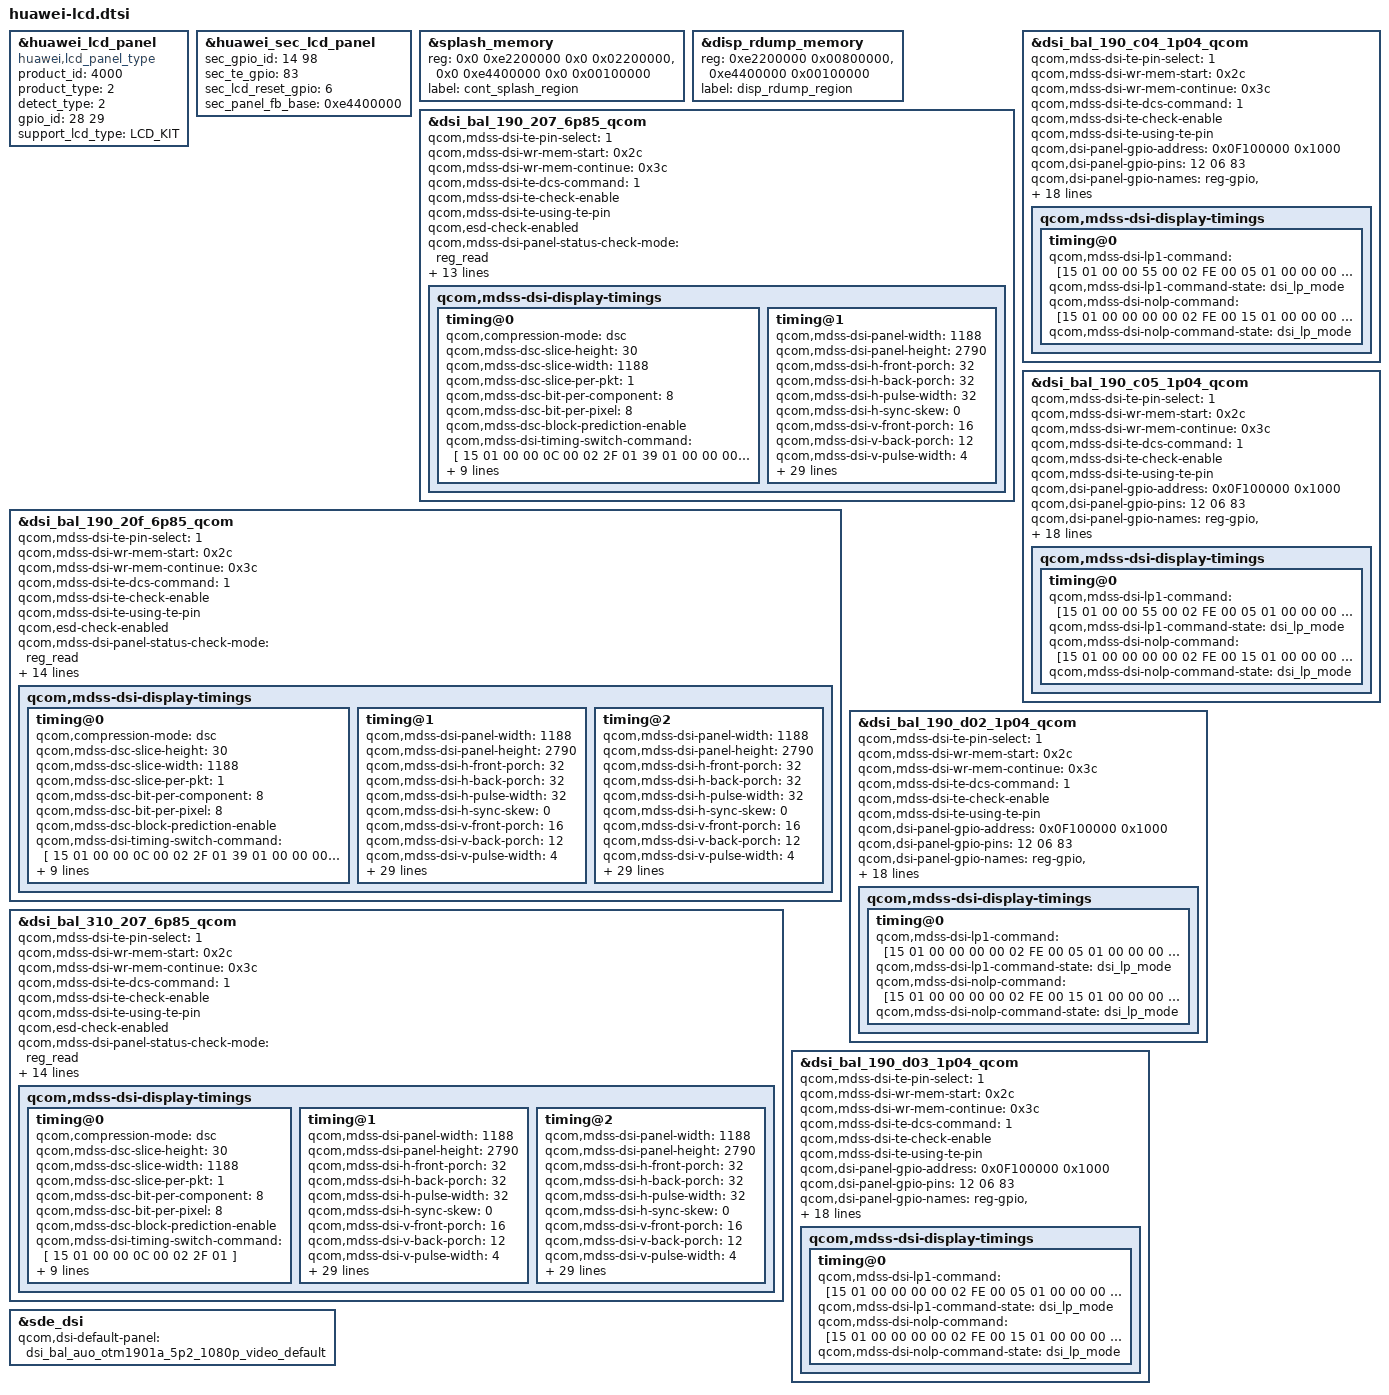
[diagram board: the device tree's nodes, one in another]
#include "../../../lcdkit3.0/bal/devkit_lcd_kit.dtsi"
&huawei_lcd_panel {
	compatible = "huawei,lcd_panel_type";
	/* auto_key_info @ name: product_id type: uint32 default: 0 */
	product_id = <4000>;
	/* auto_key_info @ name: product_type type: uint32 default: 0 */
	product_type = <2>;
	detect_type = <2>;
	/* auto_key_info @ name: gpio_id[2] type: int default: 0 */
	gpio_id = <28 29>;
	support_lcd_type = "LCD_KIT";
};

&huawei_sec_lcd_panel {
	/* auto_key_info @ name: sec_gpio_id[2] type: int default: 0 */
	sec_gpio_id = <14 98>;
	/* auto_key_info @ name: sec_te_gpio type: int default: 0 */
	sec_te_gpio = <83>;
	/* auto_key_info @ name: sec_lcd_reset_gpio type: int default: 0 */
	sec_lcd_reset_gpio = <6>;
	/* auto_key_info @ name: sec_panel_fb_base type: UINTN default: 0 */
	sec_panel_fb_base = <0xe4400000>;
};

&splash_memory {
	reg = <0x0 0xe2200000 0x0 0x02200000>, <0x0 0xe4400000 0x0 0x00100000>;
	label = "cont_splash_region";
};

&disp_rdump_memory {
	reg = <0xe2200000 0x00800000>, <0xe4400000 0x00100000>;
	label = "disp_rdump_region";
};

&dsi_bal_190_207_6p85_qcom {
	qcom,mdss-dsi-te-pin-select = <1>;
	qcom,mdss-dsi-wr-mem-start = <0x2c>;
	qcom,mdss-dsi-wr-mem-continue = <0x3c>;
	qcom,mdss-dsi-te-dcs-command = <1>;
	qcom,mdss-dsi-te-check-enable;
	qcom,mdss-dsi-te-using-te-pin;
	qcom,esd-check-enabled;
	qcom,mdss-dsi-panel-status-check-mode = "reg_read";
	qcom,mdss-dsi-panel-status-command = [06 01 00 01 00 00 01 0a];
	qcom,mdss-dsi-panel-status-command-state = "dsi_lp_mode";
	qcom,mdss-dsi-panel-status-value = <0x9c>;
	qcom,mdss-dsi-panel-status-read-length = <1>;
	qcom,dsi-panel-gpio-address = <0x0F100000 0x1000>;
	qcom,dsi-panel-gpio-pins = <12 24 82>;
	qcom,dsi-panel-gpio-names = "reg-gpio", "reset-gpio", "platform-te-gpio";
	qcom,dynamic-mode-switch-enabled;
	qcom,dynamic-mode-switch-type = "dynamic-resolution-switch-immediate";
	qcom,mdss-dsi-display-timings {
		timing@0 {
			qcom,compression-mode = "dsc";
			qcom,mdss-dsc-slice-height = <30>;
			qcom,mdss-dsc-slice-width = <1188>;
			qcom,mdss-dsc-slice-per-pkt = <1>;
			qcom,mdss-dsc-bit-per-component = <8>;
			qcom,mdss-dsc-bit-per-pixel = <8>;
			qcom,mdss-dsc-block-prediction-enable;
			qcom,mdss-dsi-timing-switch-command = [
				15 01 00 00 0C 00 02 2F 01
				39 01 00 00 00 00 06 F0 55 AA 52 08 00
				39 01 00 00 00 00 0F C5 55 55 55 55 00 05 00 55 55 55 55 55 55 55
			];
			qcom,mdss-dsi-lp1-command = [39 01 00 00 00 00 06 F0 55 AA 52 08 00
				15 01 00 00 00 00 02 6F 0D
				15 01 00 00 00 00 02 B5 51
				15 01 00 00 00 00 02 2F 01
				39 01 00 00 00 00 0F C5 55 55 55 55 00 05 00 55 55 55 55 55 55 55
				05 01 00 00 22 00 01 39
 				15 01 00 00 00 00 02 65 01
				05 01 00 00 00 00 01 2C];
			qcom,mdss-dsi-lp1-command-state = "dsi_lp_mode";
			qcom,mdss-dsi-nolp-command = [39 01 00 00 00 00 06 F0 55 AA 52 08 00
				15 01 00 00 00 00 02 6F 0D
				15 01 00 00 00 00 02 B5 50
				15 01 00 00 22 00 02 65 00
				39 01 00 00 00 00 05 51 00 00 00 00
				05 01 00 00 00 00 01 38
				05 01 00 00 00 00 01 2C
				15 01 00 00 22 00 02 2F 01
				39 01 00 00 00 00 0F C5 55 55 55 55 00 05 00 55 55 55 55 55 55 55];
			qcom,mdss-dsi-nolp-command-state = "dsi_lp_mode";
			qcom,panel-roi-alignment = <0 0 594 30 1188 30>;
			qcom,partial-update-enabled = "single_roi";
			qcom,mdss-mdp-transfer-time-us = <15245>;
		};
		timing@1 {
			qcom,mdss-dsi-panel-width = <1188>;
			qcom,mdss-dsi-panel-height = <2790>;
			qcom,mdss-dsi-h-front-porch = <32>;
			qcom,mdss-dsi-h-back-porch = <32>;
			qcom,mdss-dsi-h-pulse-width = <32>;
			qcom,mdss-dsi-h-sync-skew = <0>;
			qcom,mdss-dsi-v-front-porch = <16>;
			qcom,mdss-dsi-v-back-porch = <12>;
			qcom,mdss-dsi-v-pulse-width = <4>;
			qcom,mdss-dsi-panel-framerate = <90>;
			qcom,mdss-dsi-panel-phy-timings= [00 1B 06 06 16 20 07
				07 07 07 02 04 17 0B];
			qcom,display-topology  = <1 1 1>;
			qcom,default-topology-index  = <0>;
			qcom,mdss-dsi-on-command = [39 01 00 00 00 00 06 F0 55 AA 52 00 00
				39 01 00 00 00 00 05 FF AA 55 A5 80
				39 01 00 00 00 00 05 FF AA 55 A5 81
				39 01 00 00 00 00 05 FF AA 55 A5 00
				05 01 00 00 00 00 01 35
				15 01 00 00 00 00 02 53 20
				39 01 00 00 00 00 05 2A 00 00 04 A3
				39 01 00 00 00 00 05 2B 00 00 0A E5
				15 01 00 00 00 00 02 82 A8
				15 01 00 00 00 00 02 03 01
				15 01 00 00 00 00 02 90 01
				39 01 00 00 00 00 13 91 89 28 00 1E C2 00 03 52 03 FC 00 10 03 50 01 8B 10 F0
				05 01 00 00 00 00 01 2C
				15 01 00 00 00 00 02 2F 02
				39 01 00 00 00 00 06 F0 55 AA 52 08 00
				39 01 00 00 00 00 0F C5 55 55 55 55 00 05 00 55 55 55 55 55 55 55
				39 01 00 00 00 00 06 F0 55 AA 52 08 00
				15 01 00 00 00 00 02 6F 05
				39 01 00 00 00 00 06 B5 7F 4E 1C 4F 54
				15 01 00 00 00 00 02 6F 0B
				39 01 00 00 00 00 05 B5 4E 25 50 54
				15 01 00 00 00 00 02 6F 10
				39 01 00 00 00 00 06 B5 1C 1C 1C 1C 1C
				39 01 00 00 00 00 06 F0 55 AA 52 08 00
				15 01 00 00 00 00 02 6F 08
				15 01 00 00 00 00 02 B5 50
				15 01 00 00 00 00 02 6F 0D
				15 01 00 00 00 00 02 B5 50
				39 01 00 00 00 00 06 F0 55 AA 52 08 07
				15 01 00 00 00 00 02 C0 00
				05 01 00 00 50 00 01 11
				05 01 00 00 00 00 01 29];
			qcom,mdss-dsi-on-command-state = "dsi_lp_mode";
			qcom,mdss-dsi-off-command = [39 01 00 00 00 00 06 F0 55 AA 52 08 00
				15 01 00 00 00 00 02 6F 0D
				15 01 00 00 00 00 02 B5 50
				15 01 00 00 22 00 02 65 00
				05 01 00 00 00 00 01 38
				05 01 00 00 00 00 01 2C
				05 01 00 00 00 00 01 28
				05 01 00 00 50 00 01 10];
			qcom,mdss-dsi-off-command-state = "dsi_lp_mode";
			qcom,mdss-dsi-lp1-command = [39 01 00 00 00 00 06 F0 55 AA 52 08 00
				15 01 00 00 00 00 02 6F 0D
				15 01 00 00 00 00 02 B5 51
				15 01 00 00 00 00 02 2F 01
				39 01 00 00 00 00 0F C5 55 55 55 55 00 05 00 55 55 55 55 55 55 55
				05 01 00 00 22 00 01 39
 				15 01 00 00 00 00 02 65 01
				05 01 00 00 00 00 01 2C];
			qcom,mdss-dsi-lp1-command-state = "dsi_lp_mode";
			qcom,mdss-dsi-nolp-command = [39 01 00 00 00 00 06 F0 55 AA 52 08 00
				15 01 00 00 00 00 02 6F 0D
				15 01 00 00 00 00 02 B5 50
				15 01 00 00 22 00 02 65 00
				39 01 00 00 00 00 05 51 00 00 00 00
				05 01 00 00 00 00 01 38
				05 01 00 00 00 00 01 2C
				15 01 00 00 22 00 02 2F 02
				39 01 00 00 00 00 0F C5 55 55 55 55 00 05 00 55 55 55 55 55 55 55];
			qcom,mdss-dsi-nolp-command-state = "dsi_lp_mode";
			qcom,compression-mode = "dsc";
			qcom,mdss-dsc-slice-height = <30>;
			qcom,mdss-dsc-slice-width = <1188>;
			qcom,mdss-dsc-slice-per-pkt = <1>;
			qcom,mdss-dsc-bit-per-component = <8>;
			qcom,mdss-dsc-bit-per-pixel = <8>;
			qcom,mdss-dsc-block-prediction-enable;
			qcom,mdss-dsi-timing-switch-command = [
				15 01 00 00 09 00 02 2F 02
				39 01 00 00 00 00 06 F0 55 AA 52 08 00
				39 01 00 00 00 00 0F C5 55 55 55 55 00 05 00 55 55 55 55 55 55 55
			];
			qcom,panel-roi-alignment = <0 0 594 30 1188 30>;
			qcom,partial-update-enabled = "single_roi";
			qcom,mdss-mdp-transfer-time-us = <10164>;
		};
	};
};


&dsi_bal_190_20f_6p85_qcom {
	qcom,mdss-dsi-te-pin-select = <1>;
	qcom,mdss-dsi-wr-mem-start = <0x2c>;
	qcom,mdss-dsi-wr-mem-continue = <0x3c>;
	qcom,mdss-dsi-te-dcs-command = <1>;
	qcom,mdss-dsi-te-check-enable;
	qcom,mdss-dsi-te-using-te-pin;
	qcom,esd-check-enabled;
	qcom,mdss-dsi-panel-status-check-mode = "reg_read";
	qcom,mdss-dsi-panel-status-command = [06 01 00 01 00 00 01 0a];
	qcom,mdss-dsi-panel-status-command-state = "dsi_lp_mode";
	qcom,mdss-dsi-panel-status-value = <0x9c>;
	qcom,mdss-dsi-panel-status-read-length = <1>;
	qcom,dsi-panel-gpio-address = <0x0F100000 0x1000>;
	qcom,dsi-panel-gpio-pins = <12 24 82>;
	qcom,dsi-panel-gpio-names = "reg-gpio", "reset-gpio", "platform-te-gpio";
	qcom,dynamic-mode-switch-enabled;
	qcom,dynamic-mode-switch-type = "dynamic-resolution-switch-immediate";
	lcd-kit,panel-support-fps-list = <60 90 120>;
	qcom,mdss-dsi-display-timings {
		timing@0 {
			qcom,compression-mode = "dsc";
			qcom,mdss-dsc-slice-height = <30>;
			qcom,mdss-dsc-slice-width = <1188>;
			qcom,mdss-dsc-slice-per-pkt = <1>;
			qcom,mdss-dsc-bit-per-component = <8>;
			qcom,mdss-dsc-bit-per-pixel = <8>;
			qcom,mdss-dsc-block-prediction-enable;
			qcom,mdss-dsi-timing-switch-command = [
				15 01 00 00 0C 00 02 2F 01
				39 01 00 00 00 00 06 F0 55 AA 52 08 00
				39 01 00 00 00 00 0F C5 55 55 55 55 00 05 00 55 55 55 55 55 55 55
			];
			qcom,mdss-dsi-lp1-command = [39 01 00 00 00 00 06 F0 55 AA 52 08 00
				15 01 00 00 00 00 02 6F 0D
				15 01 00 00 00 00 02 B5 51
				15 01 00 00 00 00 02 2F 01
				39 01 00 00 00 00 0F C5 55 55 55 55 00 05 00 55 55 55 55 55 55 55
				05 01 00 00 22 00 01 39
 				15 01 00 00 00 00 02 65 01
				05 01 00 00 00 00 01 2C];
			qcom,mdss-dsi-lp1-command-state = "dsi_lp_mode";
			qcom,mdss-dsi-nolp-command = [39 01 00 00 00 00 06 F0 55 AA 52 08 00
				15 01 00 00 00 00 02 6F 0D
				15 01 00 00 00 00 02 B5 50
				15 01 00 00 22 00 02 65 00
				39 01 00 00 00 00 05 51 00 00 00 00
				05 01 00 00 00 00 01 38
				05 01 00 00 00 00 01 2C
				15 01 00 00 22 00 02 2F 01
				39 01 00 00 00 00 0F C5 55 55 55 55 00 05 00 55 55 55 55 55 55 55];
			qcom,mdss-dsi-nolp-command-state = "dsi_lp_mode";
			qcom,panel-roi-alignment = <0 0 594 30 1188 30>;
			qcom,partial-update-enabled = "single_roi";
			qcom,mdss-mdp-transfer-time-us = <15245>;
		};
		timing@1 {
			qcom,mdss-dsi-panel-width = <1188>;
			qcom,mdss-dsi-panel-height = <2790>;
			qcom,mdss-dsi-h-front-porch = <32>;
			qcom,mdss-dsi-h-back-porch = <32>;
			qcom,mdss-dsi-h-pulse-width = <32>;
			qcom,mdss-dsi-h-sync-skew = <0>;
			qcom,mdss-dsi-v-front-porch = <16>;
			qcom,mdss-dsi-v-back-porch = <12>;
			qcom,mdss-dsi-v-pulse-width = <4>;
			qcom,mdss-dsi-panel-framerate = <90>;
			qcom,mdss-dsi-panel-phy-timings= [00 1B 06 06 16 20 07
				07 07 07 02 04 17 0B];
			qcom,display-topology  = <1 1 1>;
			qcom,default-topology-index  = <0>;
			qcom,mdss-dsi-on-command = [39 01 00 00 00 00 06 F0 55 AA 52 00 00
				39 01 00 00 00 00 05 FF AA 55 A5 80
				15 01 00 00 00 00 02 6F 1D
				15 01 00 00 00 00 02 F2 05
				39 01 00 00 00 00 05 FF AA 55 A5 81
				39 01 00 00 00 00 05 FF AA 55 A5 00
				05 01 00 00 00 00 01 35
				15 01 00 00 00 00 02 53 20
				39 01 00 00 00 00 05 51 00 00 00 00
				39 01 00 00 00 00 05 2A 00 00 04 A3
				39 01 00 00 00 00 05 2B 00 00 0A E5
				15 01 00 00 00 00 02 82 A8
				15 01 00 00 00 00 02 03 01
				15 01 00 00 00 00 02 90 01
				39 01 00 00 00 00 13 91 89 28 00 1E C2 00 03 52 03 FC 00 10 03 50 01 8B 10 F0
				05 01 00 00 00 00 01 2C
				15 01 00 00 00 00 02 2F 02
				39 01 00 00 00 00 06 F0 55 AA 52 08 00
				39 01 00 00 00 00 0F C5 55 55 55 55 00 05 00 55 55 55 55 55 55 55
				39 01 00 00 00 00 06 F0 55 AA 52 08 00
				15 01 00 00 00 00 02 6F 05
				39 01 00 00 00 00 06 B5 7F 4E 1C 4F 54
				15 01 00 00 00 00 02 6F 0B
				39 01 00 00 00 00 05 B5 4E 25 50 54
				15 01 00 00 00 00 02 6F 10
				39 01 00 00 00 00 06 B5 1C 1C 1C 1C 1C
				39 01 00 00 00 00 06 F0 55 AA 52 08 00
				15 01 00 00 00 00 02 6F 08
				15 01 00 00 00 00 02 B5 50
				15 01 00 00 00 00 02 6F 0D
				15 01 00 00 00 00 02 B5 50
				39 01 00 00 00 00 06 F0 55 AA 52 08 07
				15 01 00 00 00 00 02 C0 00
				05 01 00 00 50 00 01 11
				05 01 00 00 00 00 01 29];
			qcom,mdss-dsi-on-command-state = "dsi_lp_mode";
			qcom,mdss-dsi-off-command = [39 01 00 00 00 00 06 F0 55 AA 52 08 00
				15 01 00 00 00 00 02 6F 0D
				15 01 00 00 00 00 02 B5 50
				15 01 00 00 22 00 02 65 00
				05 01 00 00 00 00 01 38
				05 01 00 00 00 00 01 2C
				05 01 00 00 00 00 01 28
				05 01 00 00 50 00 01 10];
			qcom,mdss-dsi-off-command-state = "dsi_lp_mode";
			qcom,mdss-dsi-lp1-command = [39 01 00 00 00 00 06 F0 55 AA 52 08 00
				15 01 00 00 00 00 02 6F 0D
				15 01 00 00 00 00 02 B5 51
				15 01 00 00 00 00 02 2F 01
				39 01 00 00 00 00 0F C5 55 55 55 55 00 05 00 55 55 55 55 55 55 55
				05 01 00 00 22 00 01 39
 				15 01 00 00 00 00 02 65 01
				05 01 00 00 00 00 01 2C];
			qcom,mdss-dsi-lp1-command-state = "dsi_lp_mode";
			qcom,mdss-dsi-nolp-command = [39 01 00 00 00 00 06 F0 55 AA 52 08 00
				15 01 00 00 00 00 02 6F 0D
				15 01 00 00 00 00 02 B5 50
				15 01 00 00 22 00 02 65 00
				39 01 00 00 00 00 05 51 00 00 00 00
				05 01 00 00 00 00 01 38
				05 01 00 00 00 00 01 2C
				15 01 00 00 22 00 02 2F 02
				39 01 00 00 00 00 0F C5 55 55 55 55 00 05 00 55 55 55 55 55 55 55];
			qcom,mdss-dsi-nolp-command-state = "dsi_lp_mode";
			qcom,compression-mode = "dsc";
			qcom,mdss-dsc-slice-height = <30>;
			qcom,mdss-dsc-slice-width = <1188>;
			qcom,mdss-dsc-slice-per-pkt = <1>;
			qcom,mdss-dsc-bit-per-component = <8>;
			qcom,mdss-dsc-bit-per-pixel = <8>;
			qcom,mdss-dsc-block-prediction-enable;
			qcom,mdss-dsi-timing-switch-command = [
				15 01 00 00 09 00 02 2F 02
				39 01 00 00 00 00 06 F0 55 AA 52 08 00
				39 01 00 00 00 00 0F C5 55 55 55 55 00 05 00 55 55 55 55 55 55 55
			];
			qcom,panel-roi-alignment = <0 0 594 30 1188 30>;
			qcom,partial-update-enabled = "single_roi";
			qcom,mdss-mdp-transfer-time-us = <10164>;
		};
		timing@2 {
			qcom,mdss-dsi-panel-width = <1188>;
			qcom,mdss-dsi-panel-height = <2790>;
			qcom,mdss-dsi-h-front-porch = <32>;
			qcom,mdss-dsi-h-back-porch = <32>;
			qcom,mdss-dsi-h-pulse-width = <32>;
			qcom,mdss-dsi-h-sync-skew = <0>;
			qcom,mdss-dsi-v-front-porch = <16>;
			qcom,mdss-dsi-v-back-porch = <12>;
			qcom,mdss-dsi-v-pulse-width = <4>;
			qcom,mdss-dsi-panel-framerate = <120>;
			qcom,mdss-dsi-panel-phy-timings= [00 22 08 08 19 17 09
				08 08 09 02 04 1C 0D];
			qcom,display-topology  = <1 1 1>;
			qcom,default-topology-index  = <0>;
			qcom,mdss-dsi-on-command = [39 01 00 00 00 00 06 F0 55 AA 52 00 00
				39 01 00 00 00 00 05 FF AA 55 A5 80
				15 01 00 00 00 00 02 6F 1D
				15 01 00 00 00 00 02 F2 05
				39 01 00 00 00 00 05 FF AA 55 A5 81
				39 01 00 00 00 00 05 FF AA 55 A5 00
				05 01 00 00 00 00 01 35
				15 01 00 00 00 00 02 53 20
				39 01 00 00 00 00 05 51 00 00 00 00
				39 01 00 00 00 00 05 2A 00 00 04 A3
				39 01 00 00 00 00 05 2B 00 00 0A E5
				15 01 00 00 00 00 02 82 A8
				15 01 00 00 00 00 02 03 01
				15 01 00 00 00 00 02 90 01
				39 01 00 00 00 00 13 91 89 28 00 1E C2 00 03 52 03 FC 00 10 03 50 01 8B 10 F0
				05 01 00 00 00 00 01 2C
				15 01 00 00 00 00 02 2F 03
				39 01 00 00 00 00 06 F0 55 AA 52 08 00
				39 01 00 00 00 00 0F C6 66 66 66 66 00 06 00 66 66 66 66 66 66 66
				39 01 00 00 00 00 06 F0 55 AA 52 08 00
				15 01 00 00 00 00 02 6F 05
				39 01 00 00 00 00 06 B5 7F 4E 1C 4F 54
				15 01 00 00 00 00 02 6F 0B
				39 01 00 00 00 00 05 B5 4E 25 50 54
				15 01 00 00 00 00 02 6F 10
				39 01 00 00 00 00 06 B5 1C 1C 1C 1C 1C
				39 01 00 00 00 00 06 F0 55 AA 52 08 00
				15 01 00 00 00 00 02 6F 08
				15 01 00 00 00 00 02 B5 50
				15 01 00 00 00 00 02 6F 0D
				15 01 00 00 00 00 02 B5 50
				39 01 00 00 00 00 06 F0 55 AA 52 08 07
				15 01 00 00 00 00 02 C0 00
				05 01 00 00 50 00 01 11
				05 01 00 00 00 00 01 29];
			qcom,mdss-dsi-on-command-state = "dsi_lp_mode";
			qcom,mdss-dsi-off-command = [39 01 00 00 00 00 06 F0 55 AA 52 08 00
				15 01 00 00 00 00 02 6F 0D
				15 01 00 00 00 00 02 B5 50
				15 01 00 00 22 00 02 65 00
				05 01 00 00 00 00 01 38
				05 01 00 00 00 00 01 2C
				05 01 00 00 00 00 01 28
				05 01 00 00 50 00 01 10];
			qcom,mdss-dsi-off-command-state = "dsi_lp_mode";
			qcom,mdss-dsi-lp1-command = [39 01 00 00 00 00 06 F0 55 AA 52 08 00
				15 01 00 00 00 00 02 6F 0D
				15 01 00 00 00 00 02 B5 51
				15 01 00 00 00 00 02 2F 01
				39 01 00 00 00 00 0F C5 55 55 55 55 00 05 00 55 55 55 55 55 55 55
				05 01 00 00 22 00 01 39
 				15 01 00 00 00 00 02 65 01
				05 01 00 00 00 00 01 2C];
			qcom,mdss-dsi-lp1-command-state = "dsi_lp_mode";
			qcom,mdss-dsi-nolp-command = [39 01 00 00 00 00 06 F0 55 AA 52 08 00
				15 01 00 00 00 00 02 6F 0D
				15 01 00 00 00 00 02 B5 50
				15 01 00 00 22 00 02 65 00
				39 01 00 00 00 00 05 51 00 00 00 00
				05 01 00 00 00 00 01 38
				05 01 00 00 00 00 01 2C
				15 01 00 00 22 00 02 2F 03
				39 01 00 00 00 00 0F C6 66 66 66 66 00 06 00 66 66 66 66 66 66 66];
			qcom,mdss-dsi-nolp-command-state = "dsi_lp_mode";
			qcom,compression-mode = "dsc";
			qcom,mdss-dsc-slice-height = <30>;
			qcom,mdss-dsc-slice-width = <1188>;
			qcom,mdss-dsc-slice-per-pkt = <1>;
			qcom,mdss-dsc-bit-per-component = <8>;
			qcom,mdss-dsc-bit-per-pixel = <8>;
			qcom,mdss-dsc-block-prediction-enable;
			qcom,mdss-dsi-timing-switch-command = [
				15 01 00 00 00 00 02 2F 03
				39 01 00 00 00 00 06 F0 55 AA 52 08 00
				39 01 00 00 00 00 0F C6 66 66 66 66 00 06 00 66 66 66 66 66 66 66
			];
			qcom,panel-roi-alignment = <0 0 594 30 1188 30>;
			qcom,partial-update-enabled = "single_roi";
			qcom,mdss-mdp-transfer-time-us = <7623>;
		};
	};
};

&dsi_bal_310_207_6p85_qcom {
	qcom,mdss-dsi-te-pin-select = <1>;
	qcom,mdss-dsi-wr-mem-start = <0x2c>;
	qcom,mdss-dsi-wr-mem-continue = <0x3c>;
	qcom,mdss-dsi-te-dcs-command = <1>;
	qcom,mdss-dsi-te-check-enable;
	qcom,mdss-dsi-te-using-te-pin;
	qcom,esd-check-enabled;
	qcom,mdss-dsi-panel-status-check-mode = "reg_read";
	qcom,mdss-dsi-panel-status-command = [06 01 00 01 00 00 01 0a];
	qcom,mdss-dsi-panel-status-command-state = "dsi_lp_mode";
	qcom,mdss-dsi-panel-status-value = <0x9c>;
	qcom,mdss-dsi-panel-status-read-length = <1>;
	qcom,dsi-panel-gpio-address = <0x0F100000 0x1000>;
	qcom,dsi-panel-gpio-pins = <12 24 82>;
	qcom,dsi-panel-gpio-names = "reg-gpio", "reset-gpio", "platform-te-gpio";
	qcom,dynamic-mode-switch-enabled;
	qcom,dynamic-mode-switch-type = "dynamic-resolution-switch-immediate";
	lcd-kit,panel-support-fps-list = <60 90 120>;
	qcom,mdss-dsi-display-timings {
		timing@0 {
			qcom,compression-mode = "dsc";
			qcom,mdss-dsc-slice-height = <30>;
			qcom,mdss-dsc-slice-width = <1188>;
			qcom,mdss-dsc-slice-per-pkt = <1>;
			qcom,mdss-dsc-bit-per-component = <8>;
			qcom,mdss-dsc-bit-per-pixel = <8>;
			qcom,mdss-dsc-block-prediction-enable;
			qcom,mdss-dsi-timing-switch-command = [
				15 01 00 00 0C 00 02 2F 01
			];
			qcom,mdss-dsi-lp1-command = [39 01 00 00 00 00 06 F0 55 AA 52 08 00
				15 01 00 00 00 00 02 6F 0D
				15 01 00 00 00 00 02 B5 51
				15 01 00 00 00 00 02 2F 01
				05 01 00 00 22 00 01 39
				05 01 00 00 00 00 01 2C];
			qcom,mdss-dsi-lp1-command-state = "dsi_lp_mode";
			qcom,mdss-dsi-nolp-command = [39 01 00 00 00 00 06 F0 55 AA 52 08 00
				15 01 00 00 00 00 02 6F 0D
				15 01 00 00 00 00 02 B5 50
				39 01 00 00 00 00 05 51 00 00 00 00
				05 01 00 00 00 00 01 38
				05 01 00 00 00 00 01 2C
				15 01 00 00 22 00 02 2F 01];
			qcom,mdss-dsi-nolp-command-state = "dsi_lp_mode";
			qcom,panel-roi-alignment = <0 0 594 30 1188 30>;
			qcom,partial-update-enabled = "single_roi";
			qcom,mdss-mdp-transfer-time-us = <15245>;
		};
		timing@1 {
			qcom,mdss-dsi-panel-width = <1188>;
			qcom,mdss-dsi-panel-height = <2790>;
			qcom,mdss-dsi-h-front-porch = <32>;
			qcom,mdss-dsi-h-back-porch = <32>;
			qcom,mdss-dsi-h-pulse-width = <32>;
			qcom,mdss-dsi-h-sync-skew = <0>;
			qcom,mdss-dsi-v-front-porch = <16>;
			qcom,mdss-dsi-v-back-porch = <12>;
			qcom,mdss-dsi-v-pulse-width = <4>;
			qcom,mdss-dsi-panel-framerate = <90>;
			qcom,mdss-dsi-panel-phy-timings= [00 1B 06 06 16 20 07
				07 07 07 02 04 17 0B];
			qcom,display-topology  = <1 1 1>;
			qcom,default-topology-index  = <0>;
			qcom,mdss-dsi-on-command = [ 39 01 00 00 00 00 06 F0 55 AA 52 08 00
				15 01 00 00 00 00 02 6F 06
				15 01 00 00 00 00 02 B5 4E
				39 01 00 00 00 00 06 F0 55 AA 52 08 08
				39 01 00 00 00 00 03 C0 8E FF
				39 01 00 00 00 00 06 F0 55 AA 52 08 04
				39 01 00 00 00 00 11 CB 86 10 20 40 80 C0 00 01 01 6A 02 BD 05 03 0D BB
				39 01 00 00 00 00 05 D0 00 00 00 00
				15 01 00 00 00 00 02 03 01
				15 01 00 00 00 00 02 90 01
				39 01 00 00 00 00 13 91 89 A8 00 1E C2 00 03 52 03 FC 00 10 03 50 01 8B 10 F0
				05 01 00 00 00 00 01 2C
				39 01 00 00 00 00 05 51 00 00 00 00
				15 01 00 00 00 00 02 53 20
				15 01 00 00 00 00 02 35 00
				15 01 00 00 00 00 02 82 A7
				39 01 00 00 00 00 05 2A 00 00 04 A3
				39 01 00 00 00 00 05 2B 00 00 0A E5
				15 01 00 00 00 00 02 2F 02
				05 01 00 00 50 00 01 11
				05 01 00 00 00 00 01 29];
			qcom,mdss-dsi-on-command-state = "dsi_lp_mode";
			qcom,mdss-dsi-off-command = [05 01 00 00 00 00 01 28
				05 01 00 00 50 00 01 10];
			qcom,mdss-dsi-off-command-state = "dsi_lp_mode";
			qcom,mdss-dsi-lp1-command = [39 01 00 00 00 00 06 F0 55 AA 52 08 00
				15 01 00 00 00 00 02 6F 0D
				15 01 00 00 00 00 02 B5 51
				15 01 00 00 00 00 02 2F 01
				05 01 00 00 22 00 01 39
				05 01 00 00 00 00 01 2C];
			qcom,mdss-dsi-lp1-command-state = "dsi_lp_mode";
			qcom,mdss-dsi-nolp-command = [39 01 00 00 00 00 06 F0 55 AA 52 08 00
				15 01 00 00 00 00 02 6F 0D
				15 01 00 00 00 00 02 B5 50
				39 01 00 00 00 00 05 51 00 00 00 00
				05 01 00 00 00 00 01 38
				05 01 00 00 00 00 01 2C
				15 01 00 00 22 00 02 2F 02];
			qcom,mdss-dsi-nolp-command-state = "dsi_lp_mode";
			qcom,compression-mode = "dsc";
			qcom,mdss-dsc-slice-height = <30>;
			qcom,mdss-dsc-slice-width = <1188>;
			qcom,mdss-dsc-slice-per-pkt = <1>;
			qcom,mdss-dsc-bit-per-component = <8>;
			qcom,mdss-dsc-bit-per-pixel = <8>;
			qcom,mdss-dsc-block-prediction-enable;
			qcom,mdss-dsi-timing-switch-command = [
				15 01 00 00 09 00 02 2F 02
			];
			qcom,panel-roi-alignment = <0 0 594 30 1188 30>;
			qcom,partial-update-enabled = "single_roi";
			qcom,mdss-mdp-transfer-time-us = <10164>;
		};
		timing@2 {
			qcom,mdss-dsi-panel-width = <1188>;
			qcom,mdss-dsi-panel-height = <2790>;
			qcom,mdss-dsi-h-front-porch = <32>;
			qcom,mdss-dsi-h-back-porch = <32>;
			qcom,mdss-dsi-h-pulse-width = <32>;
			qcom,mdss-dsi-h-sync-skew = <0>;
			qcom,mdss-dsi-v-front-porch = <16>;
			qcom,mdss-dsi-v-back-porch = <12>;
			qcom,mdss-dsi-v-pulse-width = <4>;
			qcom,mdss-dsi-panel-framerate = <120>;
			qcom,mdss-dsi-panel-phy-timings= [00 22 08 08 19 17 09
				08 08 09 02 04 1C 0D];
			qcom,display-topology  = <1 1 1>;
			qcom,default-topology-index  = <0>;
			qcom,mdss-dsi-on-command = [39 01 00 00 00 00 06 F0 55 AA 52 08 00
				15 01 00 00 00 00 02 6F 06
				15 01 00 00 00 00 02 B5 4E
				39 01 00 00 00 00 06 F0 55 AA 52 08 08
				39 01 00 00 00 00 03 C0 8E FF
				39 01 00 00 00 00 06 F0 55 AA 52 08 04
				39 01 00 00 00 00 11 CB 86 10 20 40 80 C0 00 01 01 6A 02 BD 05 03 0D BB
				39 01 00 00 00 00 05 D0 00 00 00 00
				15 01 00 00 00 00 02 03 01
				15 01 00 00 00 00 02 90 01
				39 01 00 00 00 00 13 91 89 A8 00 1E C2 00 03 52 03 FC 00 10 03 50 01 8B 10 F0
				05 01 00 00 00 00 01 2C
				39 01 00 00 00 00 05 51 00 00 00 00
				15 01 00 00 00 00 02 53 20
				15 01 00 00 00 00 02 35 00
				15 01 00 00 00 00 02 82 A7
				39 01 00 00 00 00 05 2A 00 00 04 A3
				39 01 00 00 00 00 05 2B 00 00 0A E5
				15 01 00 00 00 00 02 2F 03
				05 01 00 00 50 00 01 11
				05 01 00 00 00 00 01 29];
			qcom,mdss-dsi-on-command-state = "dsi_lp_mode";
			qcom,mdss-dsi-off-command = [05 01 00 00 00 00 01 28
				05 01 00 00 50 00 01 10];
			qcom,mdss-dsi-off-command-state = "dsi_lp_mode";
			qcom,mdss-dsi-lp1-command = [39 01 00 00 00 00 06 F0 55 AA 52 08 00
				15 01 00 00 00 00 02 6F 0D
				15 01 00 00 00 00 02 B5 51
				15 01 00 00 00 00 02 2F 01
				05 01 00 00 22 00 01 39
				05 01 00 00 00 00 01 2C];
			qcom,mdss-dsi-lp1-command-state = "dsi_lp_mode";
			qcom,mdss-dsi-nolp-command = [39 01 00 00 00 00 06 F0 55 AA 52 08 00
				15 01 00 00 00 00 02 6F 0D
				15 01 00 00 00 00 02 B5 50
				39 01 00 00 00 00 05 51 00 00 00 00
				05 01 00 00 00 00 01 38
				05 01 00 00 00 00 01 2C
				15 01 00 00 22 00 02 2F 03];
			qcom,mdss-dsi-nolp-command-state = "dsi_lp_mode";
			qcom,compression-mode = "dsc";
			qcom,mdss-dsc-slice-height = <30>;
			qcom,mdss-dsc-slice-width = <1188>;
			qcom,mdss-dsc-slice-per-pkt = <1>;
			qcom,mdss-dsc-bit-per-component = <8>;
			qcom,mdss-dsc-bit-per-pixel = <8>;
			qcom,mdss-dsc-block-prediction-enable;
			qcom,mdss-dsi-timing-switch-command = [
				15 01 00 00 00 00 02 2F 03
			];
			qcom,panel-roi-alignment = <0 0 594 30 1188 30>;
			qcom,partial-update-enabled = "single_roi";
			qcom,mdss-mdp-transfer-time-us = <7623>;
		};
	};
};

&dsi_bal_190_c04_1p04_qcom {
	qcom,mdss-dsi-te-pin-select = <1>;
	qcom,mdss-dsi-wr-mem-start = <0x2c>;
	qcom,mdss-dsi-wr-mem-continue = <0x3c>;
	qcom,mdss-dsi-te-dcs-command = <1>;
	qcom,mdss-dsi-te-check-enable;
	qcom,mdss-dsi-te-using-te-pin;
	qcom,dsi-panel-gpio-address = <0x0F100000 0x1000>;
	qcom,dsi-panel-gpio-pins = <12 06 83>;
	qcom,dsi-panel-gpio-names = "reg-gpio", "reset-gpio", "platform-te-gpio";
	qcom,dsi-sec-ctrl-num = <1>;
	qcom,dsi-sec-phy-num = <1>;
	qcom,dsi-select-sec-clocks = "mux_byte_clk1", "mux_pixel_clk1";
	qcom,esd-check-enabled;
	qcom,mdss-dsi-panel-status-check-mode = "reg_read";
	qcom,mdss-dsi-panel-status-command = [06 01 00 01 00 00 01 0a];
	qcom,mdss-dsi-panel-status-command-state = "dsi_lp_mode";
	qcom,mdss-dsi-panel-status-value = <0x9c>;
	qcom,mdss-dsi-panel-status-read-length = <1>;
	qcom,mdss-dsi-sec-bl-pmic-control-type = "bl_ctrl_dcs";
	qcom,panel-sec-supply-entries = <&dsi_panel_pwr_supply>;
	qcom,mdss-dsi-display-timings {
		timing@0 {
			qcom,mdss-dsi-lp1-command = [15 01 00 00 55 00 02 FE 00
				05 01 00 00 00 00 01 39];
			qcom,mdss-dsi-lp1-command-state = "dsi_lp_mode";
			qcom,mdss-dsi-nolp-command = [15 01 00 00 00 00 02 FE 00
				15 01 00 00 00 00 02 51 00
				05 01 00 00 00 00 01 38];
			qcom,mdss-dsi-nolp-command-state = "dsi_lp_mode";
		};
	};
};

&dsi_bal_190_c05_1p04_qcom {
	qcom,mdss-dsi-te-pin-select = <1>;
	qcom,mdss-dsi-wr-mem-start = <0x2c>;
	qcom,mdss-dsi-wr-mem-continue = <0x3c>;
	qcom,mdss-dsi-te-dcs-command = <1>;
	qcom,mdss-dsi-te-check-enable;
	qcom,mdss-dsi-te-using-te-pin;
	qcom,dsi-panel-gpio-address = <0x0F100000 0x1000>;
	qcom,dsi-panel-gpio-pins = <12 06 83>;
	qcom,dsi-panel-gpio-names = "reg-gpio", "reset-gpio", "platform-te-gpio";
	qcom,dsi-sec-ctrl-num = <1>;
	qcom,dsi-sec-phy-num = <1>;
	qcom,dsi-select-sec-clocks = "mux_byte_clk1", "mux_pixel_clk1";
	qcom,esd-check-enabled;
	qcom,mdss-dsi-panel-status-check-mode = "reg_read";
	qcom,mdss-dsi-panel-status-command = [06 01 00 01 00 00 01 0a];
	qcom,mdss-dsi-panel-status-command-state = "dsi_lp_mode";
	qcom,mdss-dsi-panel-status-value = <0x9c>;
	qcom,mdss-dsi-panel-status-read-length = <1>;
	qcom,mdss-dsi-sec-bl-pmic-control-type = "bl_ctrl_dcs";
	qcom,panel-sec-supply-entries = <&dsi_panel_pwr_supply>;
	qcom,mdss-dsi-display-timings {
		timing@0 {
			qcom,mdss-dsi-lp1-command = [15 01 00 00 55 00 02 FE 00
				05 01 00 00 00 00 01 39];
			qcom,mdss-dsi-lp1-command-state = "dsi_lp_mode";
			qcom,mdss-dsi-nolp-command = [15 01 00 00 00 00 02 FE 00
				15 01 00 00 00 00 02 51 00
				05 01 00 00 00 00 01 38];
			qcom,mdss-dsi-nolp-command-state = "dsi_lp_mode";
		};
	};
};

&dsi_bal_190_d02_1p04_qcom {
	qcom,mdss-dsi-te-pin-select = <1>;
	qcom,mdss-dsi-wr-mem-start = <0x2c>;
	qcom,mdss-dsi-wr-mem-continue = <0x3c>;
	qcom,mdss-dsi-te-dcs-command = <1>;
	qcom,mdss-dsi-te-check-enable;
	qcom,mdss-dsi-te-using-te-pin;
	qcom,dsi-panel-gpio-address = <0x0F100000 0x1000>;
	qcom,dsi-panel-gpio-pins = <12 06 83>;
	qcom,dsi-panel-gpio-names = "reg-gpio", "reset-gpio", "platform-te-gpio";
	qcom,dsi-sec-ctrl-num = <1>;
	qcom,dsi-sec-phy-num = <1>;
	qcom,dsi-select-sec-clocks = "mux_byte_clk1", "mux_pixel_clk1";
	qcom,esd-check-enabled;
	qcom,mdss-dsi-panel-status-check-mode = "reg_read";
	qcom,mdss-dsi-panel-status-command = [06 01 00 01 00 00 01 0a];
	qcom,mdss-dsi-panel-status-command-state = "dsi_lp_mode";
	qcom,mdss-dsi-panel-status-value = <0x9c>;
	qcom,mdss-dsi-panel-status-read-length = <1>;
	qcom,mdss-dsi-sec-bl-pmic-control-type = "bl_ctrl_dcs";
	qcom,panel-sec-supply-entries = <&dsi_panel_pwr_supply>;
	qcom,mdss-dsi-display-timings {
		timing@0 {
			qcom,mdss-dsi-lp1-command = [15 01 00 00 00 00 02 FE 00
				05 01 00 00 00 00 01 39];
			qcom,mdss-dsi-lp1-command-state = "dsi_lp_mode";
			qcom,mdss-dsi-nolp-command = [15 01 00 00 00 00 02 FE 00
				15 01 00 00 00 00 02 51 00
				05 01 00 00 00 00 01 38];
			qcom,mdss-dsi-nolp-command-state = "dsi_lp_mode";
		};
	};
};

&dsi_bal_190_d03_1p04_qcom {
	qcom,mdss-dsi-te-pin-select = <1>;
	qcom,mdss-dsi-wr-mem-start = <0x2c>;
	qcom,mdss-dsi-wr-mem-continue = <0x3c>;
	qcom,mdss-dsi-te-dcs-command = <1>;
	qcom,mdss-dsi-te-check-enable;
	qcom,mdss-dsi-te-using-te-pin;
	qcom,dsi-panel-gpio-address = <0x0F100000 0x1000>;
	qcom,dsi-panel-gpio-pins = <12 06 83>;
	qcom,dsi-panel-gpio-names = "reg-gpio", "reset-gpio", "platform-te-gpio";
	qcom,dsi-sec-ctrl-num = <1>;
	qcom,dsi-sec-phy-num = <1>;
	qcom,dsi-select-sec-clocks = "mux_byte_clk1", "mux_pixel_clk1";
	qcom,esd-check-enabled;
	qcom,mdss-dsi-panel-status-check-mode = "reg_read";
	qcom,mdss-dsi-panel-status-command = [06 01 00 01 00 00 01 0a];
	qcom,mdss-dsi-panel-status-command-state = "dsi_lp_mode";
	qcom,mdss-dsi-panel-status-value = <0x9c>;
	qcom,mdss-dsi-panel-status-read-length = <1>;
	qcom,mdss-dsi-sec-bl-pmic-control-type = "bl_ctrl_dcs";
	qcom,panel-sec-supply-entries = <&dsi_panel_pwr_supply>;
	qcom,mdss-dsi-display-timings {
		timing@0 {
			qcom,mdss-dsi-lp1-command = [15 01 00 00 00 00 02 FE 00
				05 01 00 00 00 00 01 39];
			qcom,mdss-dsi-lp1-command-state = "dsi_lp_mode";
			qcom,mdss-dsi-nolp-command = [15 01 00 00 00 00 02 FE 00
				15 01 00 00 00 00 02 51 00
				05 01 00 00 00 00 01 38];
			qcom,mdss-dsi-nolp-command-state = "dsi_lp_mode";
		};
	};
};

&sde_dsi {
	qcom,dsi-default-panel = <&dsi_bal_auo_otm1901a_5p2_1080p_video_default>;
};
